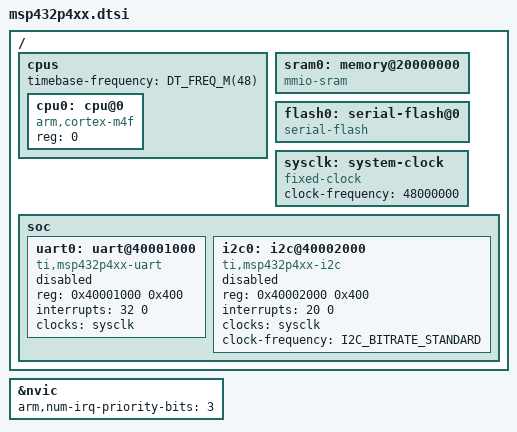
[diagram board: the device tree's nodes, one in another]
/*
 * Copyright (c) 2017 Linaro Limited
 * Copyright (c) 2026 Gail Rojas <gailroco@gmail.com>
 *
 * SPDX-License-Identifier: Apache-2.0
 */

#include <freq.h>
#include <arm/armv7-m.dtsi>
#include <zephyr/dt-bindings/i2c/i2c.h>

/ {
	cpus {
		#address-cells = <1>;
		#size-cells = <0>;
		timebase-frequency = <DT_FREQ_M(48)>;

		cpu0: cpu@0 {
			compatible = "arm,cortex-m4f";
			reg = <0>;
		};
	};

	sram0: memory@20000000 {
		compatible = "mmio-sram";
	};

	flash0: serial-flash@0 {
		compatible = "serial-flash";
	};

	sysclk: system-clock {
		compatible = "fixed-clock";
		clock-frequency = <48000000>;
		#clock-cells = <0>;
	};

	soc {
		uart0: uart@40001000 {
			compatible = "ti,msp432p4xx-uart";
			reg = <0x40001000 0x400>;
			interrupts = <32 0>;
			clocks = <&sysclk>;
			status = "disabled";
		};

		i2c0: i2c@40002000 {
			compatible = "ti,msp432p4xx-i2c";
			reg = <0x40002000 0x400>;
			interrupts = <20 0>;
			clocks = <&sysclk>;
			clock-frequency = <I2C_BITRATE_STANDARD>;
			#address-cells = <1>;
			#size-cells = <0>;
			status = "disabled";
		};
	};
};

&nvic {
	arm,num-irq-priority-bits = <3>;
};
